# STM32MP13xx register map
File version: 1.5
CPU: CA7 r0p0, little endian, MPU, FPU, 4 interrupt priority bits
Registers are 32-bit, read-write, reset 0x0 unless marked. A register's access mark holds for its fields unless they carry their own. Offsets are from the block's base; [hi:lo] are bit positions; {n}, {i} and the like mark numbered series; 'fields as' and 'values as' point back to an identical list; <NAME> marks a mode.

## ETH1 (part 3 of 4) — ETH
Base 0x5800A000
Same registers: ETH2 0x5800E000
0x910 ETH_MACL3A00R — Layer 3 Address 0 filter 0 register
  [31:0] L3A00 — Layer 3 Address 0 Field When the L3PEN0 and L3SAM0 bits are set in the ETH_MACL3L4C0R register, this field contains the value to be matched with Bits[31:0] of the IP Source Address field in the IPv6 packets. When the L3PEN0 and L3DAM0 bits are set in the ETH_MACL3L4C0R register, this field contains the value to be matched with Bits[31:0] of the IP Destination Address field in the IPv6 packets. When the L3PEN0 bit is reset and the L3SAM0 bit is set in the ETH_MACL3L4C0R register, this field contains the value to be matched with the IP Source Address field in the IPv4 packets.
0x914 ETH_MACL3A10R — Layer3 address 1 filter 0 register
  [31:0] L3A10 — Layer 3 Address 1 Field When the L3PEN0 and L3SAM0 bits are set in the ETH_MACL3L4C0R register, this field contains the value to be matched with Bits[63:32] of the IP Source Address field in the IPv6 packets. When the L3PEN0 and L3DAM0 bits are set in the ETH_MACL3L4C0R register, this field contains the value to be matched with Bits[63:32] of the IP Destination Address field in the IPv6 packets. When the L3PEN0 bit is reset and the L3SAM0 bit is set in the ETH_MACL3L4C0R register, this field contains the value to be matched with the IP Destination Address field in the IPv4 packets.
0x918 ETH_MACL3A20R — Layer3 Address 2 filter 0 register
  [31:0] L3A20 — Layer 3 Address 2 Field When the L3PEN0 and L3SAM0 bits are set in the ETH_MACL3L4C0R register, this field contains the value to be matched with Bits[95:64] of the IP Source Address field in the IPv6 packets. When the L3PEN0 and L3DAM0 bits are set in the ETH_MACL3L4C0R register, this field contains the value to be matched with Bits[95:64] of the IP Destination Address field in the IPv6 packets. When the L3PEN0 bit is reset in the ETH_MACL3L4C0R register, this field is not used.
0x91C ETH_MACL3A30R — Layer3 Address 3 filter 0 register
  [31:0] L3A30 — Layer 3 Address 3 Field When the L3PEN0 and L3SAM0 bits are set in the ETH_MACL3L4C0R register, this field contains the value to be matched with Bits[127:96] of the IP Source Address field in the IPv6 packets. When the L3PEN0 and L3DAM0 bits are set in the ETH_MACL3L4C0R register, this field contains the value to be matched with Bits[127:96] of the IP Destination Address field in the IPv6 packets. When the L3PEN0 bit is reset in the ETH_MACL3L4C0R register, this field is not used.
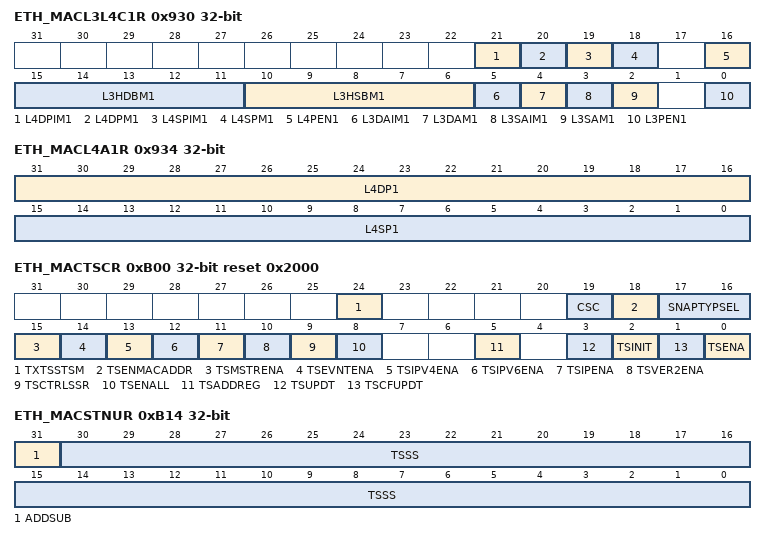
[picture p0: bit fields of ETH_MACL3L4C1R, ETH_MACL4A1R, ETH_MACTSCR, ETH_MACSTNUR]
0x930 ETH_MACL3L4C1R — L3 and L4 control 1 register
  [21] L4DPIM1 — Layer 4 Destination Port Inverse Match Enable When this bit is set, the Layer 4 Destination Port number field is enabled for inverse matching. When this bit is reset, the Layer 4 Destination Port number field is enabled for perfect matching. This bit is valid and applicable only when the L4DPM0 bit is set high.
  [20] L4DPM1 — Layer 4 Destination Port Match Enable When this bit is set, the Layer 4 Destination Port number field is enabled for matching. When this bit is reset, the MAC ignores the Layer 4 Destination Port number field for matching.
  [19] L4SPIM1 — Layer 4 Source Port Inverse Match Enable When this bit is set, the Layer 4 Source Port number field is enabled for inverse matching. When this bit is reset, the Layer 4 Source Port number field is enabled for perfect matching. This bit is valid and applicable only when the L4SPM0 bit is set high.
  [18] L4SPM1 — Layer 4 Source Port Match Enable When this bit is set, the Layer 4 Source Port number field is enabled for matching. When this bit is reset, the MAC ignores the Layer 4 Source Port number field for matching.
  [16] L4PEN1 — Layer 4 Protocol Enable When this bit is set, the Source and Destination Port number fields of UDP packets are used for matching. When this bit is reset, the Source and Destination Port number fields of TCP packets are used for matching. The Layer 4 matching is done only when the L4SPM0 or L4DPM0 bit is set.
  [15:11] L3HDBM1 — Layer 3 IP DA higher bits match This field contains the number of lower bits of IP destination address that are masked for matching in the IPv4 packets. The following list describes the values of this field: 2: Two LSbs [1:0] are masked .. 31: All bits except MSb are masked. IPv6 Packets: This field contains Bits[4:0] of L3HSBM0. These bits indicate the number of higher bits of IP source or destination address matched in the IPv6 packets. This field is valid and applicable only when the L3DAM0 or L3SAM0 bit is set high.IPv4 Packets:
    0=No bits are masked; 1=LSb[0] is masked
  [10:6] L3HSBM1 — Layer 3 IP SA Higher Bits Match IPv4 Packets: This field contains the number of lower bits of IP Source Address that are masked for matching in the IPv4 packets. The following list describes the values of this field: 2: Two LSbs [1:0] are masked .. 31: All bits except MSb are masked. IPv6 Packets: This field contains Bits[4:0] of L3HSBM0. These bits indicate the number of higher bits of IP Source or Destination Address matched in the IPv6 packets. This field is valid and applicable only when the L3DAM0 or L3SAM0 bit is set high.
    0=No bits are masked; 1=LSb[0] is masked
  [5] L3DAIM1 — Layer 3 IP DA Inverse Match Enable When this bit is set, the Layer 3 IP Destination Address field is enabled for inverse matching. When this bit is reset, the Layer 3 IP Destination Address field is enabled for perfect matching. This bit is valid and applicable only when the L3DAM0 bit is set high.
  [4] L3DAM1 — Layer 3 IP DA Match Enable When this bit is set, the Layer 3 IP Destination Address field is enabled for matching. When this bit is reset, the MAC ignores the Layer 3 IP Destination Address field for matching. Note: When the L3PEN0 bit is set, you should set either this bit or the L3SAM0 bit because either IPv6 DA or SA can be checked for filtering.
  [3] L3SAIM1 — Layer 3 IP SA Inverse Match Enable When this bit is set, the Layer 3 IP Source Address field is enabled for inverse matching. When this bit reset, the Layer 3 IP Source Address field is enabled for perfect matching. This bit is valid and applicable only when the L3SAM0 bit is set.
  [2] L3SAM1 — Layer 3 IP SA Match Enable When this bit is set, the Layer 3 IP Source Address field is enabled for matching. When this bit is reset, the MAC ignores the Layer 3 IP Source Address field for matching. Note: When the L3PEN0 bit is set, you should set either this bit or the L3DAM0 bit because either IPv6 SA or DA can be checked for filtering.
  [0] L3PEN1 — Layer 3 Protocol Enable When this bit is set, the Layer 3 IP Source or Destination Address matching is enabled for IPv6 packets. When this bit is reset, the Layer 3 IP Source or Destination Address matching is enabled for IPv4 packets. The Layer 3 matching is done only when the L3SAM0 or L3DAM0 bit is set.
0x934 ETH_MACL4A1R
  [31:16] L4DP1 — Layer 4 Destination Port Number Field When the L4PEN0 bit is reset and the L4DPM0 bit is set in the ETH_MACL3L4C0R register, this field contains the value to be matched with the TCP Destination Port Number field in the IPv4 or IPv6 packets. When the L4PEN0 and L4DPM0 bits are set in ETH_MACL3L4C0R register, this field contains the value to be matched with the UDP Destination Port Number field in the IPv4 or IPv6 packets.
  [15:0] L4SP1 — Layer 4 Source Port Number Field When the L4PEN0 bit is reset and the L4DPM0 bit is set in the ETH_MACL3L4C0R register, this field contains the value to be matched with the TCP Source Port Number field in the IPv4 or IPv6 packets. When the L4PEN0 and L4DPM0 bits are set in ETH_MACL3L4C0R register, this field contains the value to be matched with the UDP Source Port Number field in the IPv4 or IPv6 packets.
0x940 ETH_MACL3A01R — Layer3 address 0 filter 1 Register
  [31:0] L3A01 — Layer 3 Address 0 Field When the L3PEN0 and L3SAM0 bits are set in the ETH_MACL3L4C0R register, this field contains the value to be matched with Bits[31:0] of the IP Source Address field in the IPv6 packets. When the L3PEN0 and L3DAM0 bits are set in the ETH_MACL3L4C0R register, this field contains the value to be matched with Bits[31:0] of the IP Destination Address field in the IPv6 packets. When the L3PEN0 bit is reset and the L3SAM0 bit is set in the ETH_MACL3L4C0R register, this field contains the value to be matched with the IP Source Address field in the IPv4 packets.
0x944 ETH_MACL3A11R — Layer3 address 1 filter 1 register
  [31:0] L3A11 — Layer 3 Address 1 Field When the L3PEN0 and L3SAM0 bits are set in the ETH_MACL3L4C0R register, this field contains the value to be matched with Bits[63:32] of the IP Source Address field in the IPv6 packets. When the L3PEN0 and L3DAM0 bits are set in the ETH_MACL3L4C0R register, this field contains the value to be matched with Bits[63:32] of the IP Destination Address field in the IPv6 packets. When the L3PEN0 bit is reset and the L3SAM0 bit is set in the ETH_MACL3L4C0R register, this field contains the value to be matched with the IP Destination Address field in the IPv4 packets.
0x948 ETH_MACL3A21R — Layer3 address 2 filter 1 Register
  [31:0] L3A21 — Layer 3 Address 2 Field When the L3PEN0 and L3SAM0 bits are set in the ETH_MACL3L4C0R register, this field contains the value to be matched with Bits[95:64] of the IP Source Address field in the IPv6 packets. When the L3PEN0 and L3DAM0 bits are set in the ETH_MACL3L4C0R register, this field contains the value to be matched with Bits[95:64] of the IP Destination Address field in the IPv6 packets. When the L3PEN0 bit is reset in the ETH_MACL3L4C0R register, this field is not used.
0x94C ETH_MACL3A31R — Layer3 address 3 filter 1 register
  [31:0] L3A31 — Layer 3 Address 3 Field When the L3PEN0 and L3SAM0 bits are set in the ETH_MACL3L4C0R register, this field contains the value to be matched with Bits[127:96] of the IP Source Address field in the IPv6 packets. When the L3PEN0 and L3DAM0 bits are set in the ETH_MACL3L4C0R register, this field contains the value to be matched with Bits[127:96] of the IP Destination Address field in the IPv6 packets. When the L3PEN0 bit is reset in the ETH_MACL3L4C0R register, this field is not used.
0xB00 ETH_MACTSCR access per field reset 0x2000 — Timestamp control Register
  [24] TXTSSTSM rw — Transmit Timestamp Status Mode When this bit is set, the MAC overwrites the earlier transmit timestamp status even if it is not read by the software. The MAC indicates this by setting the TXTSSTSMIS bit of the ETH_MACTXTSSNR register. When this bit is reset, the MAC ignores the timestamp status of current packet if the timestamp status of previous packet is not read by the software. The MAC indicates this by setting the TXTSSTSHI bit of the ETH_MACTXTSSSR register.
  [19] CSC ro — Enable checksum correction during OST for PTP over UDP/IPv4 packets When this bit is set, the last two bytes of PTP message sent over UDP/IPv4 is updated to keep the UDP checksum correct, for changes made to origin timestamp and/or correction field as part of one step timestamp operation. The application shall form the packet with these two dummy bytes. When reset, no updates are done to keep the UDP checksum correct. The application shall form the packet with UDP checksum set to 0.
  [18] TSENMACADDR rw — Enable MAC Address for PTP Packet Filtering When this bit is set, the DA MAC address (that matches any MAC Address register) is used to filter the PTP packets when PTP is directly sent over Ethernet. When this bit is set, received PTP packets with DA containing a special multicast or unicast address that matches the one programmed in MAC address registers are considered for processing as indicated below, when PTP is directly sent over Ethernet. For normal time stamping operation, MAC address registers 0 to 31 is considered for unicast destination address matching. For PTP offload, only MAC address register 0 is considered for unicast destination address matching.
  [17:16] SNAPTYPSEL rw — Select PTP packets for Taking Snapshots These bits, along with Bits 15 and 14, decide the set of PTP packet types for which snapshot needs to be taken. The encoding is given in Timestamp Snapshot Dependency on Register Bits Table.
  [15] TSMSTRENA rw — Enable Snapshot for Messages Relevant to Master When this bit is set, the snapshot is taken only for the messages that are relevant to the master node. Otherwise, the snapshot is taken for the messages relevant to the slave node.
  [14] TSEVNTENA rw — Enable Timestamp Snapshot for Event Messages When this bit is set, the timestamp snapshot is taken only for event messages (SYNC, Delay_Req, Pdelay_Req, or Pdelay_Resp). When this bit is reset, the snapshot is taken for all messages except Announce, Management, and Signaling. For more information about the timestamp snapshots, see Timestamp Snapshot Dependency on Register Bits Table.
  [13] TSIPV4ENA rw — Enable Processing of PTP Packets Sent over IPv4-UDP When this bit is set, the MAC receiver processes the PTP packets encapsulated in IPv4-UDP packets. When this bit is reset, the MAC ignores the PTP transported over IPv4-UDP packets. This bit is set by default.
  [12] TSIPV6ENA rw — Enable Processing of PTP Packets Sent over IPv6-UDP When this bit is set, the MAC receiver processes the PTP packets encapsulated in IPv6-UDP packets. When this bit is clear, the MAC ignores the PTP transported over IPv6-UDP packets.
  [11] TSIPENA rw — Enable Processing of PTP over Ethernet Packets When this bit is set, the MAC receiver processes the PTP packets encapsulated directly in the Ethernet packets. When this bit is reset, the MAC ignores the PTP over Ethernet packets.
  [10] TSVER2ENA rw — Enable PTP Packet Processing for Version 2 Format When this bit is set, the IEEE 1588 version 2 format is used to process the PTP packets. When this bit is reset, the IEEE 1588 version 1 format is used to process the PTP packets. The IEEE 1588 formats are described in 'PTP Processing and Control'.
  [9] TSCTRLSSR rw — Timestamp Digital or Binary Rollover Control When this bit is set, the Timestamp Low register rolls over after 0x3B9A_C9FF value (that is, 1 nanosecond accuracy) and increments the timestamp (High) seconds. When this bit is reset, the rollover value of sub-second register is 0x7FFF_FFFF. The sub-second increment must be programmed correctly depending on the PTP reference clock frequency and the value of this bit.
  [8] TSENALL rw — Enable Timestamp for All Packets When this bit is set, the timestamp snapshot is enabled for all packets received by the MAC.
  [5] TSADDREG rw — Update Addend Register When this bit is set, the content of the Timestamp Addend register is updated in the PTP block for fine correction. This bit is cleared when the update is complete. This bit should be zero before it is set.
  [3] TSUPDT rw — Update Timestamp When this bit is set, the system time is updated (added or subtracted) with the value specified in ETH_MACSTSUR and ETH_MACSTNUR. This bit should be zero before updating it. This bit is reset when the update is complete in hardware.
  [2] TSINIT rw — Initialize Timestamp When this bit is set, the system time is initialized (overwritten) with the value specified in the MAC Register 80 (System Time Seconds Update Register) and MAC Register 81 (System Time Nanoseconds Update Register). This bit should be zero before it is updated. This bit is reset when the initialization is complete.
  [1] TSCFUPDT rw — Fine or Coarse Timestamp Update When this bit is set, the Fine method is used to update system timestamp. When this bit is reset, Coarse method is used to update the system timestamp.
  [0] TSENA rw — Enable Timestamp When this bit is set, the timestamp is added for Transmit and Receive packets. When disabled, timestamp is not added for transmit and receive packets and the Timestamp Generator is also suspended. You need to initialize the Timestamp (system time) after enabling this mode. On the Receive side, the MAC processes the 1588 packets only if this bit is set.
0xB04 ETH_MACSSIR — Sub-second increment register
  [23:16] SSINC — Sub-second Increment Value The value programmed in this field is accumulated every clock cycle (of clk_ptp_i) with the contents of the sub-second register. For example, when the PTP clock is 50 MHz (period is 20 ns), you should program 20 (0x14) when the System Time Nanoseconds register has an accuracy of 1 ns [Bit 9 (TSCTRLSSR) is set in ETH_MACTSCR]. When TSCTRLSSR is clear, the Nanoseconds register has a resolution of ~0.465 ns. In this case, you should program a value of 43 (0x2B) which is derived by 20 ns/0.465.
0xB08 ETH_MACSTSR ro — System time seconds register
  [31:0] TSS — Timestamp Second The value in this field indicates the current value in seconds of the System Time maintained by the MAC.
0xB0C ETH_MACSTNR ro — System time nanoseconds register
  [30:0] TSSS — Timestamp Sub-seconds The value in this field has the sub-second representation of time, with an accuracy of 0.46 ns. When Bit 9 is set in ETH_MACTSCR, each bit represents 1 ns. The maximum value is 0x3B9A_C9FF after which it rolls-over to zero.
0xB10 ETH_MACSTSUR — System time seconds update register
  [31:0] TSS — Timestamp Seconds The value in this field is the sub-second part of the update. When ADDSUB is reset, this field must be programmed with the sub-second part of the update value, with an accuracy based on the TSCTRLSSR bit of the ETH_MACTSCR register. When ADDSUB is set, then this field must be programmed with the complement of the sub-second part of the update value as described below. When TSCTRLSSR is set, then the programmed value must be 10^9 - <sub-second value>. When TSCTRLSSR is reset, then the programmed value must be 2^31 - <sub-second_value> For example, when TSCTRLSSR bit is set and if 2.000000001 seconds need to be subtracted from the system time, then the TSS field in the MAC_Timestamp Seconds update register must be 0xFFFF_FFFE (that is, 2^32 - 2), ADDSUB bit in this register should be set, and the TSSS field must be 0x3B9A_C9FF (that is, 10^9 - 1).
0xB14 ETH_MACSTNUR
  [31] ADDSUB — Add or Subtract Time When this bit is set, the time value is subtracted with the contents of the update register. When this bit is reset, the time value is added with the contents of the update register.
  [30:0] TSSS — Timestamp Sub-seconds The value in this field has the sub-second representation of time, with an accuracy of 0.46 ns. When the TSCTRLSSR bit is set in the ETH_MACTSCR register, each bit represents 1 ns and the programmed value should not exceed 0x3B9A_C9FF.
0xB18 ETH_MACTSAR — Timestamp addend register
  [31:0] TSAR — Timestamp Addend Register This field indicates the 32-bit time value to be added to the Accumulator register to achieve time synchronization.
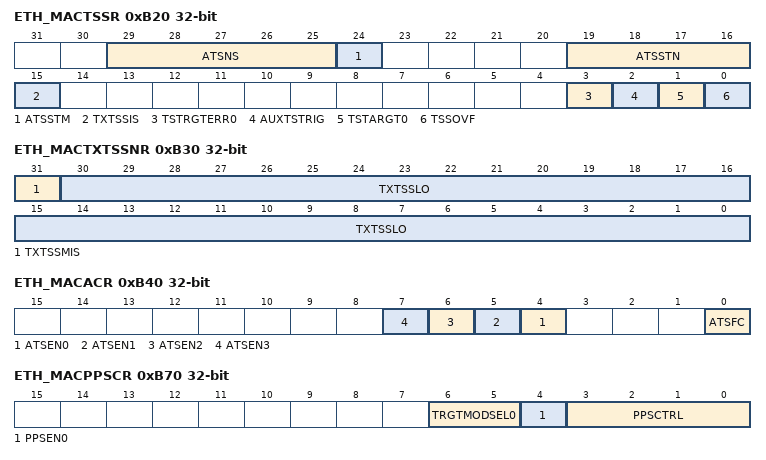
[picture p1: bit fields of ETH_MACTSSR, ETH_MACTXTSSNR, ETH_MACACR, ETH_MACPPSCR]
0xB20 ETH_MACTSSR ro — Timestamp status register
  [29:25] ATSNS — Number of Auxiliary Timestamp Snapshots This field indicates the number of Snapshots available in the FIFO. A value equal to the selected depth of FIFO (4, 8, or 16) indicates that the Auxiliary Snapshot FIFO is full. These bits are cleared (to 00000) when the Auxiliary snapshot FIFO clear bit is set.
  [24] ATSSTM — Auxiliary Timestamp Snapshot Trigger Missed This bit is set when the Auxiliary timestamp snapshot FIFO is full and external trigger was set. This indicates that the latest snapshot is not stored in the FIFO.
  [19:16] ATSSTN — Auxiliary Timestamp Snapshot Trigger Identifier These bits identify the Auxiliary trigger inputs for which the timestamp available in the Auxiliary Snapshot Register is applicable. When more than one bit is set at the same time, it means that corresponding auxiliary triggers were sampled at the same clock. These bits are applicable only if the number of Auxiliary snapshots is more than one. One bit is assigned for each trigger as shown in the following list: Bit 16: Auxiliary trigger 0 Bit 17: Auxiliary trigger 1 Bit 18: Auxiliary trigger 2 Bit 19: Auxiliary trigger 3 The software can read this register to find the triggers that are set when the timestamp is taken.
  [15] TXTSSIS — Tx Timestamp Status Interrupt Status When drop transmit status is enabled in MTL, this bit is set when the captured transmit timestamp is updated in the ETH_MACTXTSSNR and ETH_MACTXTSSSR registers. When PTP offload feature is enabled, this bit is set when the captured transmit timestamp is updated in the ETH_MACTXTSSNR and ETH_MACTXTSSSR registers, for PTO generated Delay Request and Pdelay request packets. This bit is cleared when the ETH_MACTXTSSSR register is read. This bit is reserved in all other configurations.
  [3] TSTRGTERR0 — Timestamp Target Time Error This bit is set when the latest target time programmed in the ETH_MACPPS_Target_Time_seconds and ETH_MACPPS_Target_Time_Nanoseconds registers elapses. This bit is cleared when the application reads this bit.
  [2] AUXTSTRIG — Auxiliary Timestamp Trigger Snapshot This bit is set high when the auxiliary snapshot is written to the FIFO.
  [1] TSTARGT0 — Timestamp Target Time Reached When set, this bit indicates that the value of system time is greater than or equal to the value specified in the ETH_MACPPS_Target_Time_seconds and ETH_MACPPS_Target_Time_Nanoseconds registers.
  [0] TSSOVF — Timestamp Seconds Overflow When this bit is set, it indicates that the seconds value of the timestamp (when supporting version 2 format) has overflowed beyond 32'hFFFF_FFFF.
0xB30 ETH_MACTXTSSNR ro — Tx timestamp status nanoseconds register
  [31] TXTSSMIS — Transmit Timestamp Status Missed When this bit is set, it indicates one of the following: The timestamp of the current packet is ignored if TXTSSTSM bit of the ETH_MACTSCR register is reset The timestamp of the previous packet is overwritten with timestamp of the current packet if TXTSSTSM bit of the ETH_MACTSCR register is set.
  [30:0] TXTSSLO — Transmit Timestamp Status Low This field contains the 31 bits of the Nanoseconds field of the Transmit packet's captured timestamp.
0xB34 ETH_MACTXTSSSR ro — Tx timestamp status seconds register
  [31:0] TXTSSHI — Transmit Timestamp Status High This field contains the lower 32 bits of the Seconds field of Transmit packet's captured timestamp.
0xB40 ETH_MACACR — Auxiliary control register
  [n+4] ATSEN{n} (n=0..3) — Auxiliary Snapshot {n} Enable This bit controls the capturing of Auxiliary Snapshot Trigger {n}. When this bit is set, the auxiliary snapshot of the event on eth_ptp_trg{n} input is enabled. When this bit is reset, the events on this input are ignored.
  [0] ATSFC — Auxiliary Snapshot FIFO Clear When set, this bit resets the pointers of the Auxiliary Snapshot FIFO. This bit is cleared when the pointers are reset and the FIFO is empty. When this bit is high, the auxiliary snapshots are stored in the FIFO.
0xB48 ETH_MACATSNR ro — Auxiliary timestamp nanoseconds register
  [30:0] AUXTSLO — Auxiliary Timestamp Contains the lower 31 bits (nanoseconds field) of the auxiliary timestamp.
0xB4C ETH_MACATSSR ro — Auxiliary timestamp seconds register
  [31:0] AUXTSHI — Auxiliary Timestamp Contains the lower 32 bits of the Seconds field of the auxiliary timestamp.
0xB50 ETH_MACTSIACR — Timestamp Ingress asymmetric correction register
  [31:0] OSTIAC — One-Step Timestamp Ingress Asymmetry Correction This field contains the ingress path asymmetry value to be added to correctionField of Pdelay_Resp PTP packet. The programmed value should be in units of nanoseconds and multiplied by 2^16. For example, 2.5 ns is represented as 0x00028000. The value can also be negative, which is represented in 2's complement form with bit 31 representing the sign bit.
0xB54 ETH_MACTSEACR — Timestamp Egress asymmetric correction register
  [31:0] OSTEAC — One-Step Timestamp Egress Asymmetry Correction This field contains the egress path asymmetry value to be subtracted from correctionField of Pdelay_Resp PTP packet. The programmed value must be the negated value in units of nanoseconds multiplied by 2^16. For example, if the required correction is +2.5 ns, the programmed value must be 0xFFFD_8000, which is the 2's complement of 0x0002_8000(2.5 * 216). Similarly, if the required correction is -3.3 ns, the programmed value is 0x0003_4CCC (3.3 * 216).
0xB58 ETH_MACTSICNR — Timestamp Ingress correction nanosecond register
  [31:0] TSIC — Timestamp Ingress Correction This field contains the ingress path correction value as defined by the Ingress Correction expression.
0xB5C ETH_MACTSECNR — Timestamp Egress correction nanosecond register
  [31:0] TSEC — Timestamp Egress Correction This field contains the nanoseconds part of the egress path correction value as defined by the Egress Correction expression.
0xB70 ETH_MACPPSCR — PPS control register
  [6:5] TRGTMODSEL0 — Target Time Register Mode for PPS Output This field indicates the Target Time registers (MAC registers 96 and 97) mode for PPS output signal:
    0=Target Time registers are programmed only for generating the interrupt event; 1=Reserved, must not be used; 2=Target Time registers are programmed for generating the interrupt event and starting or stopping the PPS output signal generation; 3=Target Time registers are programmed only for starting or stopping the PPS output signal generation. No interrupt is asserted.
  [4] PPSEN0 — Flexible PPS Output Mode Enable When this bit is set, Bits[3:0] function as PPSCMD. When this bit is reset, Bits[3:0] function as PPSCTRL (Fixed PPS mode).
  [3:0] PPSCTRL — PPS Output Frequency Control This field controls the frequency of the PPS output (eth_ptp_pps_out) signal. The default value of PPSCTRL is 0000, and the PPS output is 1 pulse (of width clk_ptp_i) every second. For other values of PPSCTRL, the PPS output becomes a generated clock of following frequencies: .. Note: In the binary rollover mode, the PPS output (eth_ptp_pps_out) has a duty cycle of 50 percent with these frequencies. In the digital rollover mode, the PPS output frequency is an average number. The actual clock is of different frequency that gets synchronized every second. For example: When PPSCTRL = 0001, the PPS (1 Hz) has a low period of 537 ms and a high period of 463 ms When PPSCTRL = 0010, the PPS (2 Hz) is a sequence of One clock of 50 percent duty cycle and 537 ms period Second clock of 463 ms period (268 ms low and 195 ms high) When PPSCTRL = 0011, the PPS (4 Hz) is a sequence of Three clocks of 50 percent duty cycle and 268 ms period Fourth clock of 195 ms period (134 ms low and 61 ms high) This behavior is because of the non-linear toggling of bits in the digital rollover mode in the ETH_MACSTNR register.
    1=The binary rollover is 2 Hz, and the digital rollover is 1 Hz; 2=The binary rollover is 4 Hz, and the digital rollover is 2 Hz; 3=The binary rollover is 8 Hz, and the digital rollover is 4 Hz; 4=The binary rollover is 16 Hz, and the digital rollover is 8 Hz; 15=The binary rollover is 32.768 KHz and the digital rollover is 16.384 KHz
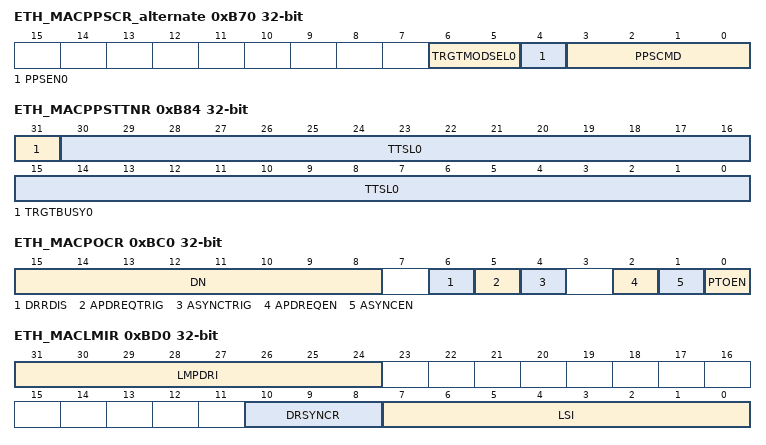
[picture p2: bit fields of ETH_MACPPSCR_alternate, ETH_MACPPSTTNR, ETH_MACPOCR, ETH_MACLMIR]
0xB70 ETH_MACPPSCR_alternate (alternate view of ETH_MACPPSCR) — PPS control register
  [6:5] TRGTMODSEL0 — Target Time Register Mode for PPS Output This field indicates the Target Time registers (MAC registers 96 and 97) mode for PPS output signal:
    values as ETH_MACPPSCR.TRGTMODSEL0
  [4] PPSEN0 — Flexible PPS Output Mode Enable When this bit is set, Bits[3:0] function as PPSCMD. When this bit is reset, Bits[3:0] function as PPSCTRL (Fixed PPS mode).
  [3:0] PPSCMD — Flexible PPS Output (eth_ptp_pps_out[0]) Control Programming these bits with a non-zero value instructs the MAC to initiate an event. When the command is transferred or synchronized to the PTP clock domain, these bits get cleared automatically. The software should ensure that these bits are programmed only when they are 'all-zero'. The following list describes the values of PPSCMD0: This command generates single pulse rising at the start point defined in Target Time Registers (register 455 and 456) and of a duration defined in the PPS Width Register. This command generates the train of pulses rising at the start point defined in the Target Time Registers and of a duration defined in the PPS Width Register and repeated at interval defined in the PPS Interval Register. By default, the PPS pulse train is free-running unless stopped by the 'Stop Pulse train at time' or 'Stop Pulse Train immediately' commands. This command cancels the START Single Pulse and START Pulse Train commands if the system time has not crossed the programmed start time. This command stops the train of pulses initiated by the START Pulse Train command (PPSCMD = 0010) after the time programmed in the Target Time registers elapses. This command immediately stops the train of pulses initiated by the START Pulse Train command (PPSCMD = 0010). This command cancels the STOP pulse train at time command if the programmed stop time has not elapsed. The PPS pulse train becomes free-running on the successful execution of this command.
    0=No Command; 1=START Single Pulse; 2=START Pulse Train; 3=Cancel START; 4=STOP Pulse train at time; 5=STOP Pulse Train immediately; 6=Cancel STOP Pulse train; {v}=Reserved, must not be used (v=7..15)
0xB80 ETH_MACPPSTTSR — PPS target time seconds register
  [31:0] TSTRH0 — PPS Target Time Seconds Register This field stores the time in seconds. When the timestamp value matches or exceeds both Target Timestamp registers, the MAC starts or stops the PPS signal output and generates an interrupt (if enabled) based on Target Time mode selected for the corresponding PPS output in the ETH_MACPPSCR register.
0xB84 ETH_MACPPSTTNR — PPS target time nanoseconds register
  [31] TRGTBUSY0 — PPS Target Time Register Busy The MAC sets this bit when the PPSCMD0 field in the ETH_MACPPSCR register is programmed to 010 or 011. Programming the PPSCMD0 field to 010 or 011 instructs the MAC to synchronize the Target Time Registers to the PTP clock domain. The MAC clears this bit after synchronizing the Target Time Registers to the PTP clock domain The application must not update the Target Time Registers when this bit is read as 1. Otherwise, the synchronization of the previous programmed time gets corrupted.
  [30:0] TTSL0 — Target Time Low for PPS Register This register stores the time in (signed) nanoseconds. When the value of the timestamp matches the value in both Target Timestamp registers, the MAC starts or stops the PPS signal output and generates an interrupt (if enabled) based on the TRGTMODSEL0 field (Bits [6:5]) in ETH_MACPPSCR. When the TSCTRLSSR bit is set in the ETH_MACTSCR register, this value should not exceed 0x3B9A_C9FF. The actual start or stop time of the PPS signal output may have an error margin up to one unit of sub-second increment value.
0xB88 ETH_MACPPSIR — PPS interval register
  [31:0] PPSINT0 — PPS Output Signal Interval These bits store the interval between the rising edges of PPS signal output. The interval is stored in terms of number of units of sub-second increment value. You need to program one value less than the required interval. For example, if the PTP reference clock is 50 MHz (period of 20 ns), and desired interval between the rising edges of PPS signal output is 100 ns (that is, 5 units of sub-second increment value), you should program value 4 (5-1) in this register.
0xB8C ETH_MACPPSWR — PPS width register
  [31:0] PPSWIDTH0 — PPS Output Signal Width These bits store the width between the rising edge and corresponding falling edge of PPS signal output. The width is stored in terms of number of units of sub-second increment value. You need to program one value less than the required interval. For example, if PTP reference clock is 50 MHz (period of 20 ns), and width between the rising and corresponding falling edges of PPS signal output is 80 ns (that is, four units of sub-second increment value), you should program value 3 (4-1) in this register. Note: The value programmed in this register must be lesser than the value programmed in ETH_MACPP0IR register.
0xBC0 ETH_MACPOCR — PTP Offload control register
  [15:8] DN — Domain Number This field indicates the domain Number in which the PTP node is operating.
  [6] DRRDIS — Disable PTO Delay Request/Response response generation When this bit is set, the Delay Request and Delay response will not be generated for received SYNC and Delay request packet respectively, as required by the programmed mode.
  [5] APDREQTRIG — Automatic PTP Pdelay_Req message Trigger When this bit is set, one PTP Pdelay_Req message is transmitted. This bit is automatically cleared after the PTP Pdelay_Req message is transmitted. The application should set the APDREQEN bit for this operation.
  [4] ASYNCTRIG — Automatic PTP SYNC message Trigger When this bit is set, one PTP SYNC message is transmitted. This bit is automatically cleared after the PTP SYNC message is transmitted. The application should set the ASYNCEN bit for this operation.
  [2] APDREQEN — Automatic PTP Pdelay_Req message Enable When this bit is set, PTP Pdelay_Req message is generated periodically based on interval programmed or trigger from application, when the MAC is programmed to be in Peer-to-Peer Transparent mode.
  [1] ASYNCEN — Automatic PTP SYNC message Enable When this bit is set, PTP SYNC message is generated periodically based on interval programmed or trigger from application, when the MAC is programmed to be in Clock Master mode.
  [0] PTOEN — PTP Offload Enable When this bit is set, the PTP Offload feature is enabled.
0xBC4 ETH_MACSPI0R — PTP Source Port Identity 0 Register
  [31:0] SPI0 — Source Port Identity 0 This field indicates bits [31:0] of sourcePortIdentity of PTP node.
0xBC8 ETH_MACSPI1R — PTP Source port identity 1 register
  [31:0] SPI1 — Source Port Identity 1 This field indicates bits [63:32] of sourcePortIdentity of PTP node.
0xBCC ETH_MACSPI2R — PTP Source port identity 2 register
  [15:0] SPI2 — Source Port Identity 2 This field indicates bits [79:64] of sourcePortIdentity of PTP node.
0xBD0 ETH_MACLMIR — Log message interval register
  [31:24] LMPDRI — Log Min Pdelay_Req Interval This field indicates logMinPdelayReqInterval of PTP node. This is used to schedule the periodic Pdelay request packet transmission. Allowed values are -15 to 15.Negative value must be represented in 2's-complement form. For example, if the required value is -1, the value programmed must be 0xFF.
  [10:8] DRSYNCR — Delay_Req to SYNC Ratio In Slave mode, it is used for controlling frequency of Delay_Req messages transmitted. 2: for every 4 SYNC messages 3: for every 8 SYNC messages 4: for every 16 SYNC messages 5: for every 32 SYNC messages Others: Reserved, must not be used The master sends this information (logMinDelayReqInterval) in the DelayResp PTP messages to the slave. The reception processes this value from the received DelayResp messages and updates this field accordingly. In the Slave mode, the host must not write/update this register unless it has to override the received value. In Master mode, the sum of this field and logSyncInterval (LSI) field is provided in the logMinDelayReqInterval field of the generated multicast Delay_Resp PTP message.
    0=DelayReq generated for every received SYNC; 1=DelayReq generated every alternate reception of SYNC
  [7:0] LSI — Log Sync Interval This field indicates the periodicity of the automatically generated SYNC message when the PTP node is Master. Allowed values are -15 to 15. Negative value must be represented in 2's-complement form. For example, if the required value is -1, the value programmed must be 0xFF.
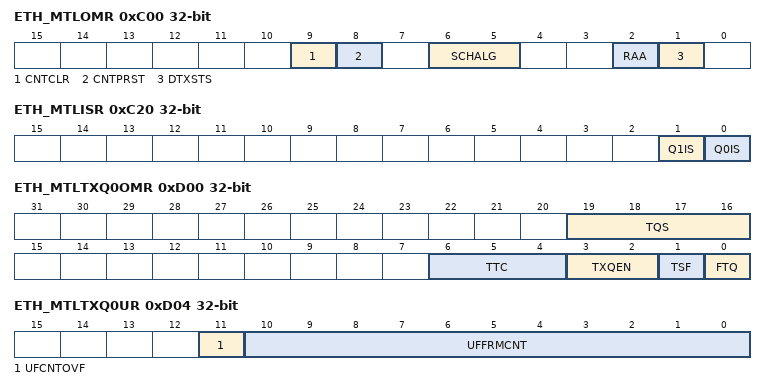
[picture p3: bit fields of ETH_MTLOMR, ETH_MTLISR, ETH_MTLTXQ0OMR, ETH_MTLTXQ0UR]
0xC00 ETH_MTLOMR — Operating mode Register
  [9] CNTCLR — Counters Reset When this bit is set, all counters are reset. This bit is cleared automatically after 1 clock cycle. If this bit is set along with CNT_PRESET bit, CNT_PRESET has precedence.
  [8] CNTPRST — Counters Preset When this bit is set: ETH_MTLTXQiUR register is initialized/preset to 0x7F0. Missed Packet and Overflow Packet counters in ETH_MTLRXQiMPOCR register is initialized/preset to 0x7F0
  [6:5] SCHALG — Tx Scheduling Algorithm This field indicates the algorithm for Tx scheduling:
    0=WRR algorithm; 1=Reserved, must not be used; 2=Reserved, must not be used; 3=Strict priority algorithm
  [2] RAA — Receive Arbitration Algorithm This field is used to select the arbitration algorithm for the Rx side. Queue 0 has the lowest priority and the last queue has the highest priority.
    0=Strict priority (SP); 1=Weighted Strict Priority (WSP)
  [1] DTXSTS — Drop Transmit Status When this bit is set, the Tx packet status received from the MAC is dropped in the MTL. When this bit is reset, the Tx packet status received from the MAC is forwarded to the application.
0xC20 ETH_MTLISR ro — Interrupt status Register
  [1] Q1IS — Queue 1 interrupt status This bit indicates that an interrupt has been generated by Queue 1. To reset this bit, read ETH_MTLQ1ICSR register to identify the interrupt cause and clear the source.
  [0] Q0IS — Queue 0 interrupt status This bit indicates that an interrupt has been generated by Queue 0. To reset this bit, read ETH_MTLQ0ICSR register to identify the interrupt cause and clear the source.
0xD00 ETH_MTLTXQ0OMR — Tx queue 0 operating mode Register
  [19:16] TQS — Transmit queue size This field indicates the size of the allocated transmit queues in blocks of 256 bytes. Queue size range from 256 bytes (TQS=0b000) to 2048 bytes (TQS=0b111).
  [6:4] TTC — Transmit Threshold Control These bits control the threshold level of the MTL Tx queue. The transmission starts when the packet size within the MTL Tx queue is larger than the threshold. In addition, full packets with length less than the threshold are also transmitted. These bits are used only when the TSF bit is reset.
    0=32; 1=64; 2=96; 3=128; 4=192; 5=256; 6=384; 7=512
  [3:2] TXQEN — Transmit Queue Enable This field is used to enable/disable the transmit queue 0. Others: Reserved, must not be used. Note: In multiple Tx queues configuration, all the queues are disabled by default. Enable the Tx queue by programming this field.
    0=Not enabled; 2=Enabled
  [1] TSF — Transmit Store and Forward When this bit is set, the transmission starts when a full packet resides in the MTL Tx queue. When this bit is set, the TTC values specified in Bits[6:4] of this register are ignored. This bit should be changed only when the transmission is stopped.
  [0] FTQ — Flush Transmit Queue When this bit is set, the Tx queue controller logic is reset to its default values. Therefore, all the data in the Tx queue is lost or flushed. This bit is internally reset when the flushing operation is complete. Until this bit is reset, you should not write to the ETH_MTLTXQ1OMR register. The data which is already accepted by the MAC transmitter is not flushed. It is scheduled for transmission and results in underflow and runt packet transmission. Note: The flush operation is complete only when the Tx queue is empty and the application has accepted the pending Tx Status of all transmitted packets. To complete this flush operation, the PHY Tx clock (eth_mii_tx_clk) should be active.
0xD04 ETH_MTLTXQ0UR ro — Tx queue 0 underflow register
  [11] UFCNTOVF — Overflow Bit for Underflow Packet Counter This bit is set every time the Tx queue Underflow Packet Counter field overflows, that is, it has crossed the maximum count. In such a scenario, the overflow packet counter is reset to all-zeros and this bit indicates that the rollover happened.
  [10:0] UFFRMCNT — Underflow Packet Counter This field indicates the number of packets aborted by the controller because of Tx queue Underflow. This counter is incremented each time the MAC aborts outgoing packet because of underflow. The counter is cleared when this register is read.
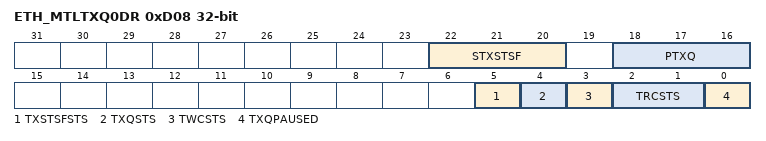
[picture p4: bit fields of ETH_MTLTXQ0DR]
0xD08 ETH_MTLTXQ0DR ro — Tx queue 0 debug Register
  [22:20] STXSTSF — Number of Status Words in Tx Status FIFO of Queue This field indicates the current number of status in the Tx Status FIFO of this queue. When the DTXSTS bit of ETH_MTLOMR register is set to 1, this field does not reflect the number of status words in Tx Status FIFO.
  [18:16] PTXQ — Number of Packets in the Transmit Queue This field indicates the current number of packets in the Tx queue. When the DTXSTS bit of ETH_MTLOMR register is set to 1, this field does not reflect the number of packets in the Transmit queue.
  [5] TXSTSFSTS — MTL Tx Status FIFO Full Status When high, this bit indicates that the MTL Tx Status FIFO is full. Therefore, the MTL cannot accept any more packets for transmission.
  [4] TXQSTS — MTL Tx Queue Not Empty Status When this bit is high, it indicates that the MTL Tx queue is not empty and some data is left for transmission.
  [3] TWCSTS — MTL Tx Queue Write Controller Status When high, this bit indicates that the MTL Tx queue Write Controller is active, and it is transferring the data to the Tx queue.
  [2:1] TRCSTS — MTL Tx Queue Read Controller Status This field indicates the state of the Tx Queue Read Controller:
    0=Idle state; 1=Read state (transferring data to the MAC transmitter); 2=Waiting for pending Tx Status from the MAC transmitter; 3=Flushing the Tx queue because of the Packet Abort request from the MAC
  [0] TXQPAUSED — Transmit Queue in Pause When this bit is high and the Rx flow control is enabled, it indicates that the Tx queue is in the Pause condition (in the full-duplex only mode) because of the following: Reception of the PFC packet for the priorities assigned to the Tx queue when PFC is enabled Reception of 802.3x Pause packet when PFC is disabled
0xD14 ETH_MTLTXQ0ESR ro — Tx queue x ETS status Register
  [23:0] ABS — Average Bits per Slot This field contains the average transmitted bits per slot. When the DCB operation is enabled for Queue x, this field is computed over every 10 million bit times slot (10 ms in 1000 Mbps; 100 ms in 100 Mbps). The maximum value is 0x989680. This bit is reserved in configurations with only one transmit queue.
0xD18 ETH_MTLTXQ0QWR — Tx queue 0 quantum weight register
  [6:0] ISCQW — Quantum weight If WRR algorithm is enabled for queue 0 generic traffic, this field contains the weight for this queue. The maximum value is 0x64.
